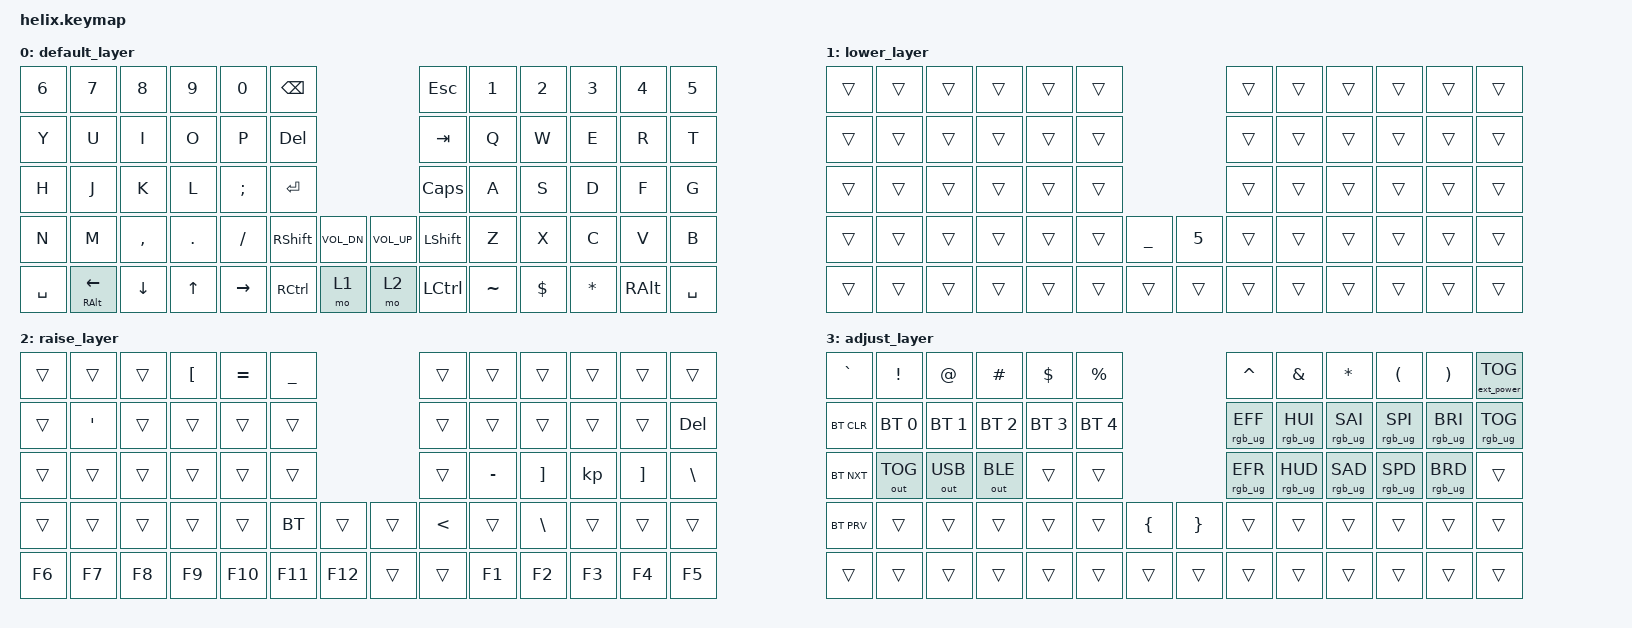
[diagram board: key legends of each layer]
/*
 * Copyright (c) 2020 The ZMK Contributors
 *mods by Sub!2023
 * SPDX-License-Identifier: MIT
 */

 #include <behaviors.dtsi>
 #include <dt-bindings/zmk/keys.h>
 #include <dt-bindings/zmk/bt.h>
 #include <dt-bindings/zmk/rgb.h>
 #include <dt-bindings/zmk/ext_power.h>
 #include <dt-bindings/zmk/outputs.h>

 #define DEFAULT 0
 #define LOWER  1
 #define RAISE  2
 #define ADJUST 3

/* NOTE: At the time of the creation of this keymap, there are no specified codes for 'eisuu' and 'kana' input in ZMK.
However, 'LANG1' and 'LANG2' are fully-functioning candidates for 'kana' and 'eisuu' input respectively.
As such, those are in use within the default layer at this time.*/

/ {
       keymap {
              compatible = "zmk,keymap";
 
              default_layer {
 // ---------------------------------------------------------------------------------------------------------------------------------
 // | GRAVE  |   1    |   2    |   3    |   4    |   5    |                                      |   6    |   7    |   8    |   9    |   0    |  DEL   |
 // |  TAB   |   Q    |   W    |   E    |   R    |   T    |                                      |   Y    |   U    |   I    |   O    |   P    |  BSPC  |
 // |  CTRL  |   A    |   S    |   D    |   F    |   G    |                                      |   H    |   J    |   K    |   L    |   ;    |   '    |
 // |  SHIFT |   Z    |   X    |   C    |   V    |   B    |  LBKT  |                    |  RBKT  |   N    |   M    |   ,    |   .    |   /    |  RET   |
 // | ADJUST |  ESC   |  ALT   |  LGUI  | EISUU  | LOWER  | SPACE  |                    |  SPACE | RAISE  |  KANA  |  LEFT  |  DOWN  |  UP    |  RIGHT |
 
 
                     bindings = <
       &kp N6    &kp N7     &kp N8      &kp N9   &kp N0    &kp BSPC                                   &kp ESCAPE   &kp N1    &kp N2    &kp N3     &kp N4    &kp N5
       &kp Y     &kp U      &kp I       &kp O    &kp P     &kp DEL                                    &kp TAB      &kp Q     &kp W     &kp E      &kp R     &kp T
       &kp H     &kp J      &kp K       &kp L    &kp SEMI  &kp RET                                    &kp CAPS     &kp A     &kp S     &kp D      &kp F     &kp G
       &kp N     &kp M      &kp COMMA   &kp DOT  &kp FSLH  &kp RSHIFT &kp C_VOL_DN      &kp C_VOL_UP  &kp LSHIFT   &kp Z     &kp X     &kp C      &kp V     &kp B
       &kp SPACE &mt RALT LEFT &kp DOWN &kp UP   &kp RIGHT &kp RCTRL  &mo 1             &mo 2         &kp LCTRL    &kp TILDE &kp DLLR  &kp STAR   &kp RALT  &kp SPACE
                     >;
              };
              lower_layer {
 // ---------------------------------------------------------------------------------------------------------------------------------
 // |      |      |      |      |      |      |                                  |      |      |      |      |      |      |
 // |  ~   |  !   |  @   |  #   |  $   |  %   |                                  |  ^   |  &   |  *   |  (   |  )   |      |
 // |      |      |      |      |      |      |                                  |      |  _   |  +   |  {   |  }   | PIPE |
 // |      |      |      |      |      |      |  (   |                    |  )   |      |      |      | HOME | END  |      |
 // |      |      |      |      |      |      |      |                    |      |      |      |      |      |      |      |
                     bindings = <
       &trans    &trans   &trans &trans   &trans   &trans                             &trans    &trans    &trans    &trans   &trans   &trans
       &trans    &trans   &trans &trans   &trans   &trans                             &trans    &trans    &trans    &trans   &trans   &trans
       &trans    &trans   &trans &trans   &trans   &trans                             &trans    &trans    &trans    &trans   &trans   &trans
       &trans    &trans   &trans &trans   &trans   &trans    &kp UNDER       &kp N5   &trans    &trans    &trans    &trans   &trans   &trans
       &trans    &trans   &trans &trans   &trans   &trans    &trans          &trans   &trans    &trans    &trans    &trans   &trans   &trans
                     >;
              }; 
              raise_layer {
 // ---------------------------------------------------------------------------------------------------------------------------------
 // |       |       |       |       |       |       |                                    |       |       |       |       |       |       |
 // |     |
 // |       |       |       |       |       |       |       |                    |       |       |       | NEXT  | VOL-  | VOL+  | PLAY  |
                     bindings = <
       &trans    &trans   &trans &kp LBKT &kp EQUAL &kp UNDER                      &trans  &trans    &trans     &trans     &trans    &trans
       &trans    &kp APOS &trans &trans   &trans    &trans                         &trans  &trans    &trans     &trans     &trans    &kp DEL
       &trans    &trans   &trans &trans   &trans    &trans                         &trans  &kp MINUS &kp RBKT   &kp        &kp RBKT  &kp BSLH
       &trans    &trans   &trans &trans   &trans    &kp BT  &trans          &trans &kp LT  &trans    &kp BSLH   &trans     &trans    &trans
       &kp F6    &kp F7   &kp F8 &kp F9   &kp F10   &kp F11 &kp F12         &trans &trans  &kp F1    &kp F2     &kp F3     &kp F4    &kp F5
                     >;
              };  
              adjust_layer {
 // ---------------------------------------------------------------------------------------------------------------------------------
 // |    `     |    !     |    @     |    #     |    $     |    %     |                                          |    ^     |    &     |    *     |    (     |    )     |  EP TOG  |
 // |  BT CLR  | BT SEL0  | BT SEL1  | BT SEL2  | BGT SEL3 | BT SEL4  |                                          | RGB EFF+ | RGB HUE+ | RGB SAT+ | RGB SPD+ | RGB BRI+ | RGB TOG  |
 // |  BT NXT  | OUT TOG  | OUT USB  | OUT BLE  |          |          |                                          | RGB EFF- | RGB HUE- | RGB SAT- | RGB SPD- | RGB BRI- |          |
 // |  BT PRV  |          |          |          |          |          |    {     |                    |    }     |          |          |          |          |          |          |
 // |          |          |          |          |          |          |          |                    |          |          |          |          |          |          |          |
                     bindings = <
       &kp GRAVE  &kp EXCL     &kp AT       &kp HASH     &kp DLLR     &kp PRCNT                             &kp CARET       &kp AMPS        &kp ASTRK       &kp LPAR        &kp RPAR        &ext_power EP_TOG
       &bt BT_CLR &bt BT_SEL 0 &bt BT_SEL 1 &bt BT_SEL 2 &bt BT_SEL 3 &bt BT_SEL 4                          &rgb_ug RGB_EFF &rgb_ug RGB_HUI &rgb_ug RGB_SAI &rgb_ug RGB_SPI &rgb_ug RGB_BRI &rgb_ug RGB_TOG 
       &bt BT_NXT &out OUT_TOG &out OUT_USB &out OUT_BLE &trans       &trans                                &rgb_ug RGB_EFR &rgb_ug RGB_HUD &rgb_ug RGB_SAD &rgb_ug RGB_SPD &rgb_ug RGB_BRD &trans
       &bt BT_PRV &trans       &trans       &trans       &trans       &trans       &kp LBRC        &kp RBRC &trans          &trans          &trans          &trans          &trans          &trans
       &trans     &trans       &trans       &trans       &trans       &trans       &trans          &trans   &trans          &trans          &trans          &trans          &trans          &trans
                     >;
              };
       };
};
